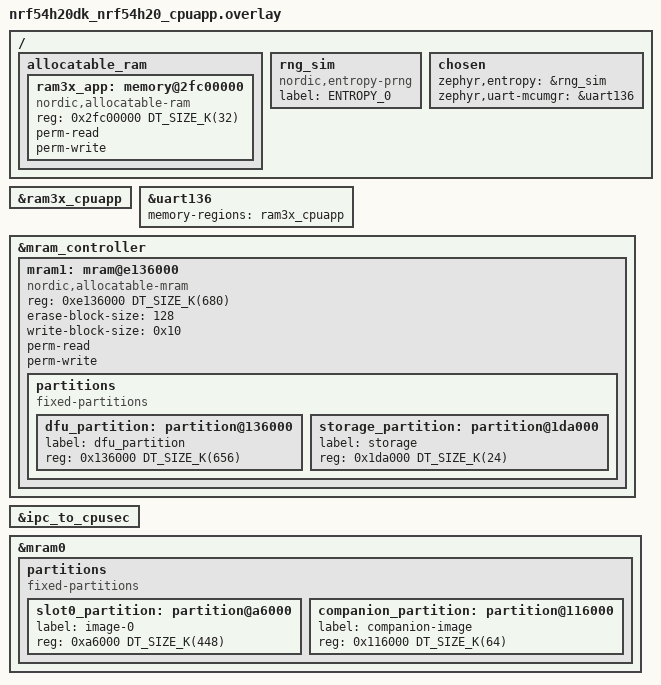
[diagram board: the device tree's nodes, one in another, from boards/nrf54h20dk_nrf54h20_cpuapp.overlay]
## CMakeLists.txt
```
#
# Copyright (c) 2023 Nordic Semiconductor ASA
#
# SPDX-License-Identifier: LicenseRef-Nordic-5-Clause
#

cmake_minimum_required(VERSION 3.13.1)

find_package(Zephyr REQUIRED HINTS $ENV{ZEPHYR_BASE})

project(suit_smp_transfer)

target_sources(app PRIVATE src/main.c)

if (CONFIG_MCUMGR_TRANSPORT_BT)
  target_sources(app PRIVATE src/bluetooth.c)
endif()

if (CONFIG_SUIT_BUILD_FLASH_COMPANION)
  foreach (overlay IN LISTS DTC_OVERLAY_FILE)
    if (EXISTS "${overlay}")
      get_filename_component(overlay_path "${overlay}" ABSOLUTE)
      add_overlay_dts(flash_companion "${overlay_path}")
    endif()
  endforeach()

  add_child_image(
    NAME flash_companion
    SOURCE_DIR ${CMAKE_SOURCE_DIR}/../flash_companion
    BOARD ${BOARD}
  )
endif()
```

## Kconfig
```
#
# Copyright (c) 2023 Nordic Semiconductor ASA
#
# SPDX-License-Identifier: LicenseRef-Nordic-5-Clause
#

config APP_VERSION
  int "Application version"
	default 1

config SUIT_ENVELOPE_SEQUENCE_NUM
  default APP_VERSION

config SUIT_SECDOM_UPDATE_LOG
  bool "Enable Secure Domain logs in update candidate"
  default n

config SUIT_BUILD_FLASH_COMPANION
  bool "Enable build of the flash companion firmware"

source "Kconfig.zephyr"
```

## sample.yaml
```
#
# Copyright (c) 2023 Nordic Semiconductor ASA
#
# SPDX-License-Identifier: LicenseRef-Nordic-5-Clause
#

sample:
  name: SUIT update through SMP sample
  description: Sample application that updates firmware using SUIT and SMP protocol
tests:
  subsys.suit.smp_transfer.nrf54h20.fpga.v1:
    extra_args: DTC_OVERLAY_FILE="boards/nrf54h20dk_nrf54h20_cpuapp_fpga.overlay"
    extra_configs:
      - CONFIG_EMULATOR_FPGA=y
      - CONFIG_APP_VERSION=1
      - CONFIG_SUIT_ENVELOPE_EDITABLE_TEMPLATES_LOCATION="./"
      - CONFIG_UART_NRFX_LEGACY_SHIM=y
    platform_allow: nrf54h20dk_nrf54h20_cpuapp@soc1 nrf54h20dk_nrf54h20_cpuapp
    build_only: true
    tags: suit fpga

  subsys.suit.smp_transfer.nrf54h20.fpga.v2:
    extra_args: DTC_OVERLAY_FILE="boards/nrf54h20dk_nrf54h20_cpuapp_fpga.overlay"
    extra_configs:
      - CONFIG_EMULATOR_FPGA=y
      - CONFIG_APP_VERSION=2
      - CONFIG_SUIT_ENVELOPE_EDITABLE_TEMPLATES_LOCATION="./"
      - CONFIG_UART_NRFX_LEGACY_SHIM=y
    platform_allow: nrf54h20dk_nrf54h20_cpuapp@soc1 nrf54h20dk_nrf54h20_cpuapp
    build_only: true
    tags: suit fpga

  subsys.suit.smp_transfer.v1:
    extra_configs:
      - CONFIG_APP_VERSION=1
      - CONFIG_SUIT_ENVELOPE_EDITABLE_TEMPLATES_LOCATION="./"
    platform_allow: nrf54h20dk_nrf54h20_cpuapp@soc1
    build_only: true
    tags: suit

  subsys.suit.smp_transfer.bt.v1:
    extra_args: OVERLAY_CONFIG="overlay-bt.conf"
    extra_configs:
      - CONFIG_APP_VERSION=1
      - CONFIG_SUIT_ENVELOPE_EDITABLE_TEMPLATES_LOCATION="./"
    platform_allow: nrf54h20dk_nrf54h20_cpuapp@soc1
    build_only: true
    tags: suit bluetooth

  subsys.suit.smp_transfer.v2:
    extra_configs:
      - CONFIG_APP_VERSION=2
      - CONFIG_SUIT_ENVELOPE_EDITABLE_TEMPLATES_LOCATION="./"
    platform_allow: nrf54h20dk_nrf54h20_cpuapp@soc1
    build_only: true
    tags: suit

  subsys.suit.smp_transfer.bt.v2:
    extra_args: OVERLAY_CONFIG="overlay-bt.conf"
    extra_configs:
      - CONFIG_APP_VERSION=2
      - CONFIG_SUIT_ENVELOPE_EDITABLE_TEMPLATES_LOCATION="./"
    platform_allow: nrf54h20dk_nrf54h20_cpuapp@soc1
    build_only: true
    tags: suit bluetooth

  subsys.suit.smp_transfer.bt.nrf54h20.fpga.v1:
    extra_args:
      OVERLAY_CONFIG="overlay-bt.conf"
      DTC_OVERLAY_FILE="boards/nrf54h20dk_nrf54h20_cpuapp_fpga.overlay"
      hci_rpmsg_CONFIG_EMULATOR_FPGA=y
    extra_configs:
      - CONFIG_EMULATOR_FPGA=y
      - CONFIG_APP_VERSION=1
      - CONFIG_SUIT_ENVELOPE_EDITABLE_TEMPLATES_LOCATION="./"
    platform_allow: nrf54h20dk_nrf54h20_cpuapp@soc1
    build_only: true
    tags: suit bluetooth fpga

  subsys.suit.smp_transfer.bt.nrf54h20.fpga.v2:
    extra_args:
      OVERLAY_CONFIG="overlay-bt.conf"
      DTC_OVERLAY_FILE="boards/nrf54h20dk_nrf54h20_cpuapp_fpga.overlay"
      hci_rpmsg_CONFIG_EMULATOR_FPGA=y
    extra_configs:
      - CONFIG_EMULATOR_FPGA=y
      - CONFIG_APP_VERSION=2
      - CONFIG_SUIT_ENVELOPE_EDITABLE_TEMPLATES_LOCATION="./"
    platform_allow: nrf54h20dk_nrf54h20_cpuapp@soc1
    build_only: true
    tags: suit bluetooth fpga
```

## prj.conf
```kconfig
#
# Copyright (c) 2023 Nordic Semiconductor ASA
#
# SPDX-License-Identifier: LicenseRef-Nordic-5-Clause
#

# Enable DK LED library
CONFIG_DK_LIBRARY=y

# Enable mcumgr
CONFIG_NET_BUF=y
CONFIG_ZCBOR=y
CONFIG_MCUMGR=y
CONFIG_MCUMGR_SMP_LEGACY_RC_BEHAVIOUR=y

# Enable the serial mcumgr transport
CONFIG_SERIAL=y
CONFIG_CONSOLE=y
CONFIG_BASE64=y
CONFIG_MCUMGR_TRANSPORT_UART=y

# Enable SUIT services
CONFIG_SUIT=y
CONFIG_MGMT_SUITFU=y
CONFIG_FLASH=y

# Enable SUIT envelope creation
CONFIG_SUIT_ENVELOPE=y
CONFIG_SUIT_ENVELOPE_HIERARCHICAL_MANIFEST=y

# Extended SUIT commands over USER group
CONFIG_MGMT_SUITFU_GRP_SUIT=y
```

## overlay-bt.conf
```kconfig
#
# Copyright (c) 2023 Nordic Semiconductor ASA
#
# SPDX-License-Identifier: LicenseRef-Nordic-5-Clause
#

CONFIG_BT=y
CONFIG_BT_PERIPHERAL=y

# Allow for large Bluetooth data packets.
CONFIG_BT_L2CAP_TX_MTU=498
CONFIG_BT_BUF_ACL_RX_SIZE=502
CONFIG_BT_BUF_ACL_TX_SIZE=502

# Enable the Bluetooth mcumgr transport (unauthenticated).
CONFIG_MCUMGR_TRANSPORT_BT=y
CONFIG_MCUMGR_TRANSPORT_BT_AUTHEN=n
CONFIG_MCUMGR_TRANSPORT_BT_CONN_PARAM_CONTROL=y

# Disable SMP over UART
CONFIG_SERIAL=n
CONFIG_CONSOLE=n
CONFIG_MCUMGR_TRANSPORT_UART=n

# Enable the mcumgr Packet Reassembly feature over Bluetooth and its configuration dependencies.
# MCUmgr buffer size is optimized to fit one SMP packet divided into five Bluetooth Write Commands,
# transmitted with the maximum possible MTU value: 498 bytes.
CONFIG_MCUMGR_TRANSPORT_BT_REASSEMBLY=y
CONFIG_MCUMGR_TRANSPORT_NETBUF_SIZE=2475
CONFIG_MCUMGR_TRANSPORT_WORKQUEUE_STACK_SIZE=4096

CONFIG_BT_DEVICE_NAME="SUIT SMP Sample"

# Add provisioning data for sample radio core application
CONFIG_SUIT_MPI_RAD_LOCAL_1=y
```

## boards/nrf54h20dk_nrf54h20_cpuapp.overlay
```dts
/*
 * Copyright (c) 2023 Nordic Semiconductor ASA
 *
 * SPDX-License-Identifier: LicenseRef-Nordic-5-Clause
 */
 #include <zephyr/dt-bindings/mbox/nrf-ids.h>


 / {
	allocatable_ram {
		#address-cells = <1>;
		#size-cells = <1>;

		/* Allow to use defined RAM3x region by App and cores owned by
		 * App, including UART DMA buffer.
		 */
		ram3x_app: memory@2fc00000 {
			compatible = "nordic,allocatable-ram";
			reg = <0x2fc00000 DT_SIZE_K(32)>;
			perm-read;
			perm-write;
		};
	};

	rng_sim: rng_sim {
		status = "okay";
		compatible = "nordic,entropy-prng";
		label = "ENTROPY_0";
	};

	chosen {
		zephyr,entropy = &rng_sim;
		zephyr,uart-mcumgr = &uart136;
	};
};

/* ram3x_cpuapp buffer is used by App core UART driver. */
&ram3x_cpuapp {
	status = "okay";
};

/* Configure SMP UART. */
&uart136 {
	status = "okay";
	memory-regions = <&ram3x_cpuapp>;
};

/delete-node/ &mram1;

&mram_controller {
	mram1: mram@e136000 {
		compatible = "nordic,allocatable-mram", "soc-nv-flash";
		reg = < 0xe136000 DT_SIZE_K(680) >;
		erase-block-size = < 128 >;
		/* Hardcoded inside the soc_flash_nrf_mram.c (MRAM_WORD_SIZE) */
		write-block-size = < 0x10 >;

		perm-read;
		perm-write;

		partitions {
			compatible = "fixed-partitions";
			#address-cells = < 0x1 >;
			#size-cells = < 0x1 >;

			/* The default application code partition ends at 0xe126000.
			 * If the application uses PPR, it extends the code partition to 0xe136000.
			 */
			dfu_partition: partition@136000 {
				label = "dfu_partition";
				reg = < 0x136000 DT_SIZE_K(656) >;
			};

			storage_partition: partition@1da000 {
				label = "storage";
				reg = < 0x1da000 DT_SIZE_K(24) >;
			};
		};
	};
};

&ipc_to_cpusec {
	status = "okay";
};

&mram0 {
	partitions {
		compatible = "fixed-partitions";
		#address-cells = < 0x1 >;
		#size-cells = < 0x1 >;
		slot0_partition: partition@a6000 {
			label = "image-0";
			reg = <0xa6000 DT_SIZE_K(448)>;
		};
		companion_partition: partition@116000 {
			label = "companion-image";
			reg = <0x116000 DT_SIZE_K(64)>;
		};
	};
};
```

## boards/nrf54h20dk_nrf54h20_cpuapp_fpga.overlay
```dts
/*
 * Copyright (c) 2023 Nordic Semiconductor ASA
 *
 * SPDX-License-Identifier: LicenseRef-Nordic-5-Clause
 */

#include "nrf54h20dk_nrf54h20_cpuapp.overlay"

&uart136 {
	/* Use higher baudrate so it will be equivalent to 115200 on VU19P FPGA */
	current-speed = < 921600 >;
};
```

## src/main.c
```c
/*
 * Copyright (c) 2023 Nordic Semiconductor ASA
 *
 * SPDX-License-Identifier: LicenseRef-Nordic-5-Clause
 */

#include <zephyr/kernel.h>
#include <dk_buttons_and_leds.h>
#ifdef CONFIG_MGMT_SUITFU
#include <suitfu_mgmt.h>
#endif /* CONFIG_MGMT_SUITFU */
#include <zephyr/storage/flash_map.h>
#include "common.h"

#ifdef CONFIG_SSF_SUIT_SERVICE_ENABLED
#include <sdfw_services/suit_service.h>
#endif /* CONFIG_SSF_SUIT_SERVICE_ENABLED */

#define DFU_PARTITION_OFFSET  FIXED_PARTITION_OFFSET(dfu_partition)
#define DFU_PARTITION_SIZE    FIXED_PARTITION_SIZE(dfu_partition)
#define DFU_PARTITION_ADDRESS suit_plat_mem_nvm_ptr_get(DFU_PARTITION_OFFSET)

int main(void)
{
	int ret = dk_leds_init();
	if (ret) {
		printk("Cannot init LEDs (err: %d)\r\n", ret);
	}

	printk("Hello world from %s version: %d\r\n", CONFIG_BOARD, CONFIG_APP_VERSION);

#if (CONFIG_SSF_SUIT_SERVICE_ENABLED) && (CONFIG_APP_VERSION == 1) && (!CONFIG_MGMT_SUITFU)
	suit_plat_mreg_t update_candidate[] = {
		{
			.mem = DFU_PARTITION_ADDRESS,
			.size = DFU_PARTITION_SIZE,
		},
	};

	printk("Validate candidate: %p (0x%x)\r\n", update_candidate[0].mem,
	       update_candidate[0].size);
	bool dfu_partition_valid =
		suit_validate_candidate(update_candidate[0].mem, update_candidate[0].size);

	printk("DFU update candidate found in DFU partition: %d\r\n", dfu_partition_valid);
	if (dfu_partition_valid) {
		int ret = suit_trigger_update(update_candidate, ARRAY_SIZE(update_candidate));
		printk("DFU triggered with status: %d\r\n", ret);
	}
#endif

#ifdef CONFIG_MCUMGR_TRANSPORT_BT
	start_smp_bluetooth();
#endif

	while (1) {
		for (int i = 0; i < CONFIG_APP_VERSION; i++) {
			dk_set_led_on(DK_LED1);
			k_msleep(250);
			dk_set_led_off(DK_LED1);
			k_msleep(250);
		}

		k_msleep(5000);
	}

	return 0;
}
```

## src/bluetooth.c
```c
/*
 * Copyright (c) 2012-2014 Wind River Systems, Inc.
 * Copyright (c) 2020 Prevas A/S
 *
 * SPDX-License-Identifier: Apache-2.0
 */

#include <zephyr/bluetooth/bluetooth.h>
#include <zephyr/bluetooth/conn.h>
#include <zephyr/bluetooth/gatt.h>
#include <zephyr/mgmt/mcumgr/transport/smp_bt.h>

#define LOG_LEVEL LOG_LEVEL_DBG
#include <zephyr/logging/log.h>
LOG_MODULE_REGISTER(smp_bt_sample);

static struct k_work advertise_work;

static const struct bt_data ad[] = {
	BT_DATA_BYTES(BT_DATA_FLAGS, (BT_LE_AD_GENERAL | BT_LE_AD_NO_BREDR)),
	BT_DATA_BYTES(BT_DATA_UUID128_ALL, 0x84, 0xaa, 0x60, 0x74, 0x52, 0x8a, 0x8b, 0x86, 0xd3,
		      0x4c, 0xb7, 0x1d, 0x1d, 0xdc, 0x53, 0x8d),
};

static void advertise(struct k_work *work)
{
	int rc;

	bt_le_adv_stop();

	rc = bt_le_adv_start(BT_LE_ADV_CONN_NAME, ad, ARRAY_SIZE(ad), NULL, 0);
	if (rc) {
		LOG_ERR("Advertising failed to start (rc %d)", rc);
		return;
	}

	LOG_INF("Advertising successfully started");
}

static void connected(struct bt_conn *conn, uint8_t err)
{
	if (err) {
		LOG_ERR("Connection failed (err 0x%02x)", err);
	} else {
		LOG_INF("Connected");
	}
}

static void disconnected(struct bt_conn *conn, uint8_t reason)
{
	LOG_INF("Disconnected (reason 0x%02x)", reason);
	k_work_submit(&advertise_work);
}

BT_CONN_CB_DEFINE(conn_callbacks) = {
	.connected = connected,
	.disconnected = disconnected,
};

static void bt_ready(int err)
{
	if (err) {
		LOG_ERR("Bluetooth init failed (err %d)", err);
		return;
	}

	LOG_INF("Bluetooth initialized");

	k_work_submit(&advertise_work);
}

void start_smp_bluetooth(void)
{
	k_work_init(&advertise_work, advertise);

	/* Enable Bluetooth. */
	int rc = bt_enable(bt_ready);

	if (rc != 0) {
		LOG_ERR("Bluetooth init failed (err %d)", rc);
		return;
	}
}
```
